AUTOSAR XML (schema 4-2-1)
package /RootP_ASWC_M740
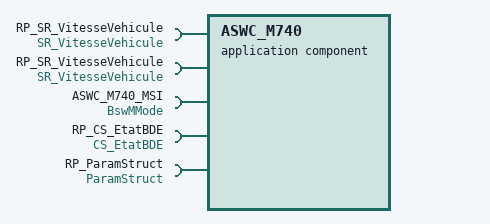
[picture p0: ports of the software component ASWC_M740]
  application sw component type ASWC_M740
    5 x require port:
      RP_SR_VitesseVehicule: required-interface=SR_VitesseVehicule
      RP_SR_VitesseVehicule: required-interface=SR_VitesseVehicule
      ASWC_M740_MSI: required-interface=BswMMode
      RP_CS_EtatBDE: required-interface=CS_EtatBDE
      RP_ParamStruct: required-interface=ParamStruct
package /RootP_Composition
  composition sw component type Compo_VSM
    component Instance_ASWC_M740: type=ASWC_M740
